# PIC32CZ1038CA70144 register map
Vendor: Microchip Technology; Series: CA70; File version: 0
CPU: CM7 r1p1, little endian, MPU, FPU, 3 interrupt priority bits
Registers are 32-bit, access not given, no defined reset value unless marked. A register's access mark holds for its fields unless they carry their own. Offsets are from the block's base; [hi:lo] are bit positions; 'fields as' and 'values as' point back to an identical list.

## I2SC0 — Inter-IC Sound Controller
Base 0x4008C000; register names take the prefix I2SC_
Same registers: I2SC1 0x40090000
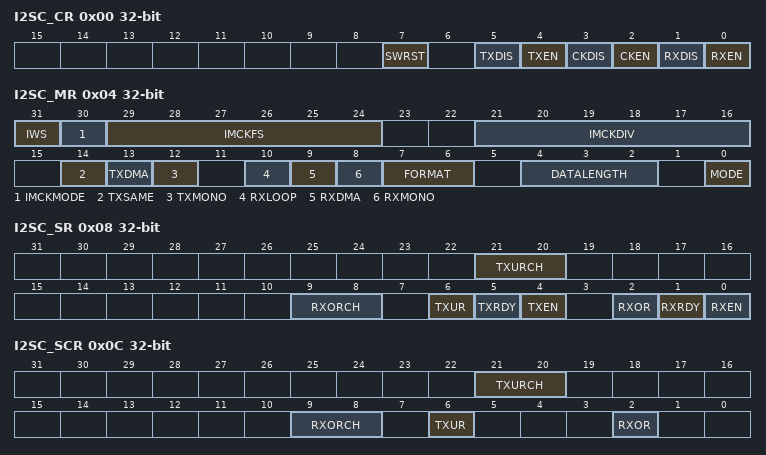
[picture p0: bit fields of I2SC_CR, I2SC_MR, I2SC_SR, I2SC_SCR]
0x00 I2SC_CR wo — Control Register
  [7] SWRST — Software Reset
  [5] TXDIS — Transmitter Disable
  [4] TXEN — Transmitter Enable
  [3] CKDIS — Clocks Disable
  [2] CKEN — Clocks Enable
  [1] RXDIS — Receiver Disable
  [0] RXEN — Receiver Enable
0x04 I2SC_MR — Mode Register
  [31] IWS — I2SC_WS Slot Width
  [30] IMCKMODE — Master Clock Mode
  [29:24] IMCKFS — Master Clock to fs Ratio
    0=M2SF32 (Sample frequency ratio set to 32); 1=M2SF64 (Sample frequency ratio set to 64); 2=M2SF96 (Sample frequency ratio set to 96); 3=M2SF128 (Sample frequency ratio set to 128); 5=M2SF192 (Sample frequency ratio set to 192); 7=M2SF256 (Sample frequency ratio set to 256); 11=M2SF384 (Sample frequency ratio set to 384); 15=M2SF512 (Sample frequency ratio set to 512); 23=M2SF768 (Sample frequency ratio set to 768); 31=M2SF1024 (Sample frequency ratio set to 1024); 47=M2SF1536 (Sample frequency ratio set to 1536); 63=M2SF2048 (Sample frequency ratio set to 2048)
  [21:16] IMCKDIV — Selected Clock to I2SC Master Clock Ratio
  [14] TXSAME — Transmit Data when Underrun
  [13] TXDMA — Single or Multiple DMA Controller Channels for Transmitter
  [12] TXMONO — Transmit Mono
  [10] RXLOOP — Loopback Test Mode
  [9] RXDMA — Single or Multiple DMA Controller Channels for Receiver
  [8] RXMONO — Receive Mono
  [7:6] FORMAT — Data Format
    0=I2S (I2S format, stereo with I2SC_WS low for left channel, and MSB of sample starting one I2SC_CK period after I2SC_WS edge); 1=LJ (Left-justified format, stereo with I2SC_WS high for left channel, and MSB of sample starting on I2SC_WS edge)
  [4:2] DATALENGTH — Data Word Length
    0=_32_BITS (Data length is set to 32 bits); 1=_24_BITS (Data length is set to 24 bits); 2=_20_BITS (Data length is set to 20 bits); 3=_18_BITS (Data length is set to 18 bits); 4=_16_BITS (Data length is set to 16 bits); 5=_16_BITS_COMPACT (Data length is set to 16-bit compact stereo. Left sample in bits 15:0 and right sample in bits 31:16 of same word.); 6=_8_BITS (Data length is set to 8 bits); 7=_8_BITS_COMPACT (Data length is set to 8-bit compact stereo. Left sample in bits 7:0 and right sample in bits 15:8 of the same word.)
  [0] MODE — Inter-IC Sound Controller Mode
    0=SLAVE (I2SC_CK and I2SC_WS pin inputs used as bit clock and word select/frame synchronization.); 1=MASTER (Bit clock and word select/frame synchronization generated by I2SC from MCK and output to I2SC_CK and I2SC_WS pins. Peripheral clock or GCLK is output as master clock on I2SC_MCK if I2SC_MR.IMCKMODE is set.)
0x08 I2SC_SR ro — Status Register
  [21:20] TXURCH — Transmit Underrun Channel
  [9:8] RXORCH — Receive Overrun Channel
  [6] TXUR — Transmit Underrun
  [5] TXRDY — Transmit Ready
  [4] TXEN — Transmitter Enabled
  [2] RXOR — Receive Overrun
  [1] RXRDY — Receive Ready
  [0] RXEN — Receiver Enabled
0x0C I2SC_SCR wo — Status Clear Register
  [21:20] TXURCH — Transmit Underrun Per Channel Status Clear
  [9:8] RXORCH — Receive Overrun Per Channel Status Clear
  [6] TXUR — Transmit Underrun Status Clear
  [2] RXOR — Receive Overrun Status Clear
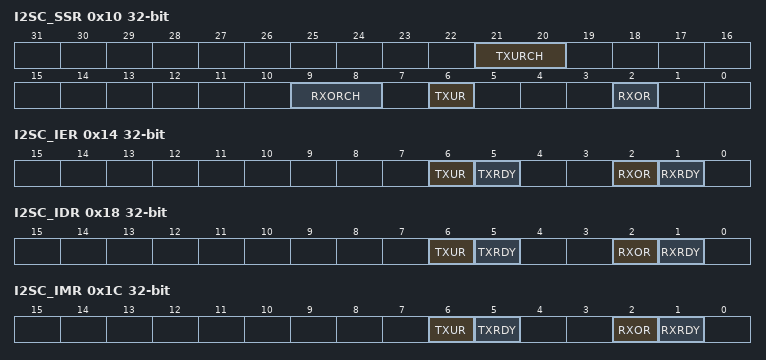
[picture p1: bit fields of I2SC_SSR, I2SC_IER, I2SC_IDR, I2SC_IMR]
0x10 I2SC_SSR wo — Status Set Register
  [21:20] TXURCH — Transmit Underrun Per Channel Status Set
  [9:8] RXORCH — Receive Overrun Per Channel Status Set
  [6] TXUR — Transmit Underrun Status Set
  [2] RXOR — Receive Overrun Status Set
0x14 I2SC_IER wo — Interrupt Enable Register
  [6] TXUR — Transmit Underflow Interrupt Enable
  [5] TXRDY — Transmit Ready Interrupt Enable
  [2] RXOR — Receiver Overrun Interrupt Enable
  [1] RXRDY — Receiver Ready Interrupt Enable
0x18 I2SC_IDR wo — Interrupt Disable Register
  [6] TXUR — Transmit Underflow Interrupt Disable
  [5] TXRDY — Transmit Ready Interrupt Disable
  [2] RXOR — Receiver Overrun Interrupt Disable
  [1] RXRDY — Receiver Ready Interrupt Disable
0x1C I2SC_IMR ro — Interrupt Mask Register
  fields as I2SC_IDR
0x20 I2SC_RHR ro — Receiver Holding Register
0x24 I2SC_THR wo — Transmitter Holding Register

## Notices in the file
Copyright (c) 2017 Microchip Technology Inc.
SPDX-License-Identifier: Apache-2.0
Licensed under the Apache License, Version 2.0 (the "License");
you may not use this file except in compliance with the License.
You may obtain a copy of the License at
http://www.apache.org/licenses/LICENSE-2.0
Unless required by applicable law or agreed to in writing, software
distributed under the License is distributed on an "AS IS" BASIS,
WITHOUT WARRANTIES OR CONDITIONS OF ANY KIND, either express or implied.
See the License for the specific language governing permissions and
limitations under the License.
